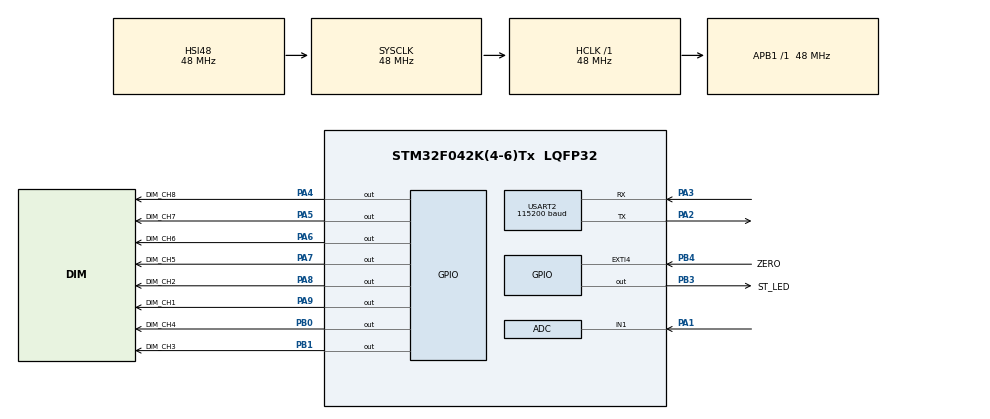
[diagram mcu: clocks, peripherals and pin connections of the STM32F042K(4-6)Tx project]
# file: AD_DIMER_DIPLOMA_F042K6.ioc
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ADC.DataAlign=ADC_DATAALIGN_RIGHT
Mcu.Family=STM32F0
Mcu.Name=STM32F042K(4-6)Tx
Mcu.Package=LQFP32
NVIC.ADC1_IRQn=true\:0\:0\:false\:false\:true\:true\:true\:true
NVIC.EXTI4_15_IRQn=true\:0\:0\:false\:false\:true\:true\:true\:true
NVIC.TIM14_IRQn=true\:0\:0\:false\:false\:true\:true\:true\:true
NVIC.TIM16_IRQn=true\:0\:0\:false\:false\:true\:true\:true\:true
NVIC.USART2_IRQn=true\:0\:0\:false\:false\:true\:true\:true\:true
PA1.GPIO_PuPd=GPIO_NOPULL
PA1.Mode=IN1
PA1.Signal=ADC_IN1
PA13.Mode=Serial_Wire
PA13.Signal=SYS_SWDIO
PA14.Mode=Serial_Wire
PA14.Signal=SYS_SWCLK
PA2.Mode=Asynchronous
PA2.Signal=USART2_TX
PA3.Mode=Asynchronous
PA3.Signal=USART2_RX
PA4.GPIO_Label=DIM_CH8
PA4.Signal=GPIO_Output
PA5.GPIO_Label=DIM_CH7
PA5.Signal=GPIO_Output
PA6.GPIO_Label=DIM_CH6
PA6.Signal=GPIO_Output
PA7.GPIO_Label=DIM_CH5
PA7.Signal=GPIO_Output
PA8.GPIO_Label=DIM_CH2
PA8.Signal=GPIO_Output
PA9.GPIO_Label=DIM_CH1
PA9.Signal=GPIO_Output
PB0.GPIO_Label=DIM_CH4
PB0.Signal=GPIO_Output
PB1.GPIO_Label=DIM_CH3
PB1.Signal=GPIO_Output
PB3.GPIO_Label=ST_LED
PB3.Signal=GPIO_Output
PB4.GPIO_Label=ZERO
PB4.Signal=GPXTI4
PF0-OSC_IN.Mode=HSE-External-Oscillator
PF0-OSC_IN.Signal=RCC_OSC_IN
PF1-OSC_OUT.Mode=HSE-External-Oscillator
PF1-OSC_OUT.Signal=RCC_OSC_OUT
ProjectManager.HeapSize=0x200
ProjectManager.StackSize=0x400
ProjectManager.TargetToolchain=STM32CubeIDE
RCC.AHBFreq_Value=48000000
RCC.APB1Freq_Value=48000000
RCC.APB1TimFreq_Value=48000000
RCC.HCLKFreq_Value=48000000
RCC.SYSCLKFreq_VALUE=48000000
RCC.SYSCLKSource=RCC_SYSCLKSOURCE_HSI48
TIM14.Period=1
TIM14.Prescaler=2400-1
TIM16.Period=500
TIM16.Prescaler=48000-1
USART2.BaudRate=115200
USART2.VirtualMode-Asynchronous=VM_ASYNC
VP_TIM14_VS_ClockSourceINT.Mode=Enable_Timer
VP_TIM16_VS_ClockSourceINT.Mode=Enable_Timer
board=custom

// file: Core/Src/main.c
/* USER CODE BEGIN Header */
/**
  ******************************************************************************
  * @file           : main.c
  * @brief          : Main program body
  ******************************************************************************
  * @attention
  *
  * Copyright (c) 2023 STMicroelectronics.
  * All rights reserved.
  *
  * This software is licensed under terms that can be found in the LICENSE file
  * in the root directory of this software component.
  * If no LICENSE file comes with this software, it is provided AS-IS.
  *
  ******************************************************************************
  */
/* USER CODE END Header */
#include "main.h"
#include "adc.h"
#include "tim.h"
#include "usart.h"
#include "gpio.h"

void SystemClock_Config(void);

/* USER CODE BEGIN 0 */

uint8_t receiveBuffer[BUFFER_SIZE];
//uint16_t adc_value = 0;
/* USER CODE END 0 */

int main(void)
{

  /* MCU Configuration--------------------------------------------------------*/

  /* Reset of all peripherals, Initializes the Flash interface and the Systick. */
  HAL_Init();

  /* Configure the system clock */
  SystemClock_Config();

  /* Initialize all configured peripherals */
  MX_GPIO_Init();
  MX_ADC_Init();
  MX_USART2_UART_Init();
  MX_TIM14_Init();
  MX_TIM16_Init();
  /* USER CODE BEGIN 2 */
  HAL_UART_Receive_IT(&huart2, receiveBuffer, BUFFER_SIZE);
  HAL_TIM_Base_Start_IT(&htim14);
  HAL_TIM_Base_Start_IT(&htim16);
  /* USER CODE END 2 */

  /* Infinite loop */
  while (1)
  {

  }
}

void SystemClock_Config(void)
{
  RCC_OscInitTypeDef RCC_OscInitStruct = {0};
  RCC_ClkInitTypeDef RCC_ClkInitStruct = {0};

  /** Initializes the RCC Oscillators according to the specified parameters
  * in the RCC_OscInitTypeDef structure.
  */
  RCC_OscInitStruct.OscillatorType = RCC_OSCILLATORTYPE_HSI14|RCC_OSCILLATORTYPE_HSI48;
  RCC_OscInitStruct.HSI48State = RCC_HSI48_ON;
  RCC_OscInitStruct.HSI14State = RCC_HSI14_ON;
  RCC_OscInitStruct.HSI14CalibrationValue = 16;
  RCC_OscInitStruct.PLL.PLLState = RCC_PLL_NONE;
  if (HAL_RCC_OscConfig(&RCC_OscInitStruct) != HAL_OK)
  {
    Error_Handler();
  }

  /** Initializes the CPU, AHB and APB buses clocks
  */
  RCC_ClkInitStruct.ClockType = RCC_CLOCKTYPE_HCLK|RCC_CLOCKTYPE_SYSCLK
                              |RCC_CLOCKTYPE_PCLK1;
  RCC_ClkInitStruct.SYSCLKSource = RCC_SYSCLKSOURCE_HSI48;
  RCC_ClkInitStruct.AHBCLKDivider = RCC_SYSCLK_DIV1;
  RCC_ClkInitStruct.APB1CLKDivider = RCC_HCLK_DIV1;

  if (HAL_RCC_ClockConfig(&RCC_ClkInitStruct, FLASH_LATENCY_1) != HAL_OK)
  {
    Error_Handler();
  }
}

void Error_Handler(void)
{
  __disable_irq();
  while (1)
  {
  }
}
